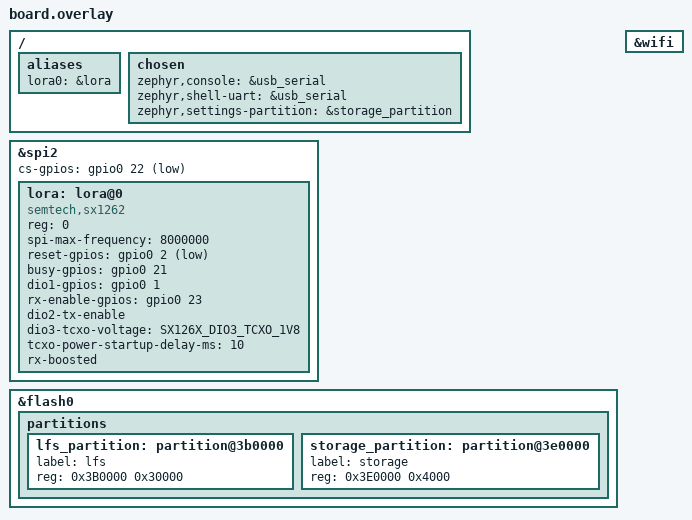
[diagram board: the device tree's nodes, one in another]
/*
 * SPDX-License-Identifier: MIT
 * XIAO ESP32-C6 + SX1262 LoRa
 *
 * Pin mapping (from Arduino MeshCore variants/xiao_c6):
 * - D4 (GPIO22) = NSS     - D8  (GPIO19) = SPI SCK
 * - D1 (GPIO1)  = DIO1    - D9  (GPIO20) = SPI MISO
 * - D3 (GPIO21) = BUSY    - D10 (GPIO18) = SPI MOSI
 * - D2 (GPIO2)  = RESET
 * - D5 (GPIO23) = RXEN
 * - GPIO15      = Yellow LED (TX indicator)
 *
 * Console: USB-Serial/JTAG (usb_serial)
 */

#include <zephyr/dt-bindings/lora/sx126x.h>

/ {
	aliases {
		lora0 = &lora;
	};

	chosen {
		zephyr,console = &usb_serial;
		zephyr,shell-uart = &usb_serial;
	};
};

/* SX1262 on SPI2 (XIAO SPI bus — SCK/MISO/MOSI already in pinctrl) */
&spi2 {
	cs-gpios = <&gpio0 22 GPIO_ACTIVE_LOW>;  /* D4 = GPIO22 NSS */

	lora: lora@0 {
		compatible = "semtech,sx1262";
		reg = <0>;
		spi-max-frequency = <8000000>;

		/* LoRa control pins */
		reset-gpios = <&gpio0 2 GPIO_ACTIVE_LOW>;    /* D2 = GPIO2 */
		busy-gpios = <&gpio0 21 GPIO_ACTIVE_HIGH>;   /* D3 = GPIO21 */
		dio1-gpios = <&gpio0 1 (GPIO_PULL_DOWN | GPIO_ACTIVE_HIGH)>;  /* D1 = GPIO1 */

		/* RF switch: RXEN for RX, DIO2 drives TX enable */
		rx-enable-gpios = <&gpio0 23 GPIO_ACTIVE_HIGH>;  /* D5 = GPIO23 RXEN */
		dio2-tx-enable;

		/* TCXO 1.8V via DIO3 */
		dio3-tcxo-voltage = <SX126X_DIO3_TCXO_1V8>;
		tcxo-power-startup-delay-ms = <10>;

		/* RX boosted mode for better sensitivity */
		rx-boosted;
	};
};

/*
 * Flash partitions — repartition default ESP32 layout.
 * Default storage_partition is 192KB at 0x3B0000.
 *
 * 0x3B0000 - 0x3E0000 (192KB) LittleFS (identity, contacts, channels, BLE bonds)
 */
/delete-node/ &storage_partition;
/delete-node/ &scratch_partition;

/ {
	chosen {
		zephyr,settings-partition = &storage_partition;
	};
};

&flash0 {
	partitions {
		/* LittleFS 192KB for DataStore (identity, prefs, contacts) */
		lfs_partition: partition@3b0000 {
			label = "lfs";
			reg = <0x3B0000 0x30000>;
		};
		/* BLE bond store — 16KB NVS, isolated from /lfs (see esp32_common.conf).
		 * Placed in the unused scratch region just above lfs (lfs unchanged). */
		storage_partition: partition@3e0000 {
			label = "storage";
			reg = <0x3E0000 0x4000>;
		};
	};
};

/* LittleFS auto-mount — standard /lfs mount point */
#include "../../common/filesystem.dtsi"

/* WiFi — required for OTA firmware updates */
&wifi {
	status = "okay";
};
